# ATSAM4LC4A device description
Architecture: CORTEX-M4; Family: SAM4; Series: SAM4L
Registers are 32-bit, read-write, reset 0x0 unless marked. A register's access mark holds for its fields unless they carry their own. Offsets are from the block's base; [hi:lo] are bit positions; {n}, {i} and the like mark numbered series.

## AESA — Advanced Encryption Standard
Instances: AESA 0x400B0000
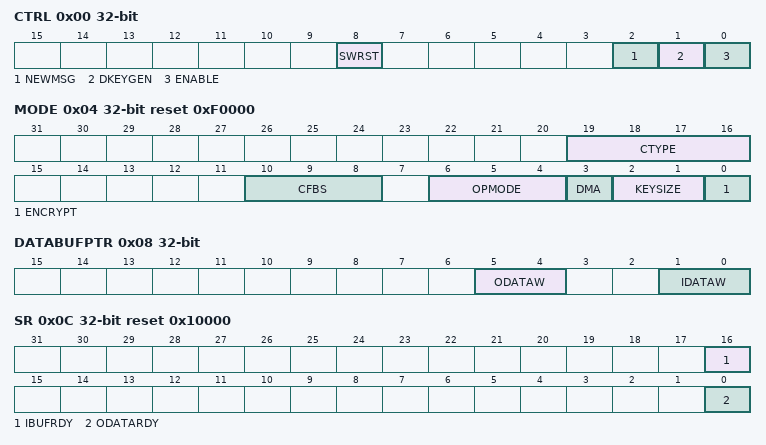
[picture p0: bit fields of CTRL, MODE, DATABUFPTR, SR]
0x00 CTRL — Control Register
  [8] SWRST — Software Reset
  [2] NEWMSG — New Message
  [1] DKEYGEN — Decryption Key Generate
  [0] ENABLE — Enable Module
0x04 MODE reset 0xF0000
  [19:16] CTYPE — Countermeasure Type
  [10:8] CFBS — Cipher Feedback Data Segment Size
  [6:4] OPMODE — Confidentiality Mode of Operation
  [3] DMA — DMA Mode
  [2:1] KEYSIZE
  [0] ENCRYPT — Encryption
0x08 DATABUFPTR — Data Buffer Pointer Register
  [5:4] ODATAW — Output Data Word
  [1:0] IDATAW — Input Data Word
0x0C SR ro reset 0x10000 — Status Register
  [16] IBUFRDY — Input Buffer Ready
  [0] ODATARDY — Output Data Ready
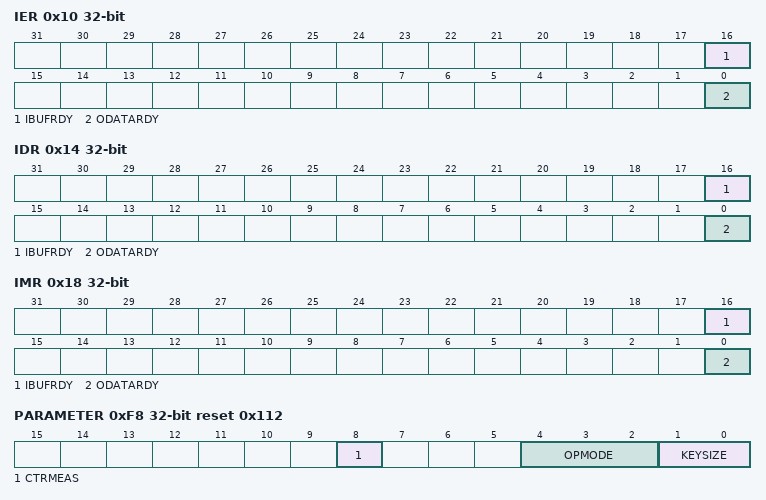
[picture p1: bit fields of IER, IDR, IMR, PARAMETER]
0x10 IER wo (atomic set of IMR) — Interrupt Enable Register
  [16] IBUFRDY — Input Buffer Ready Interrupt Enable
  [0] ODATARDY — Output Data Ready Interrupt Enable
0x14 IDR wo (atomic clear of IMR) — Interrupt Disable Register
  [16] IBUFRDY — Input Buffer Ready Interrupt Disable
  [0] ODATARDY — Output Data Ready Interrupt Disable
0x18 IMR ro — Interrupt Mask Register
  [16] IBUFRDY — Input Buffer Ready Interrupt Mask
  [0] ODATARDY — Output Data Ready Interrupt Mask
{0x20+4i} KEY[{i}] (i=0..7) wo
  [31:0] KEY0 — Key Word 0
{0x40+4i} INITVECT[{i}] (i=0..3) wo — Initialization Vector Register
  [31:0] INITVECT0 — Initialization Vector Word 0
0x50 IDATA wo — Input Data Register
  [31:0] IDATA — Input Data
0x60 ODATA ro — Output Data Register
  [31:0] ODATA — Output Data
0x70 DRNGSEED wo
  [31:0] SEED — DRNG Seed
0xF8 PARAMETER ro reset 0x112
  [8] CTRMEAS — Countermeasures
  [4:2] OPMODE — Maximum Number of Confidentiality Modes of Operation
  [1:0] KEYSIZE — Maximum Key Size
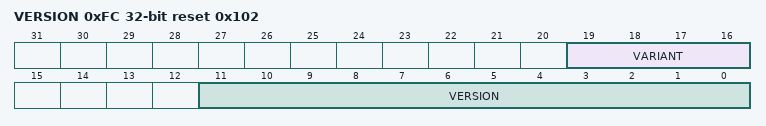
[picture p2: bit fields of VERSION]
0xFC VERSION ro reset 0x102
  [19:16] VARIANT — Variant Number
  [11:0] VERSION — Version Number

## BPM — Backup Power Manager
Instances: BPM 0x400F0000
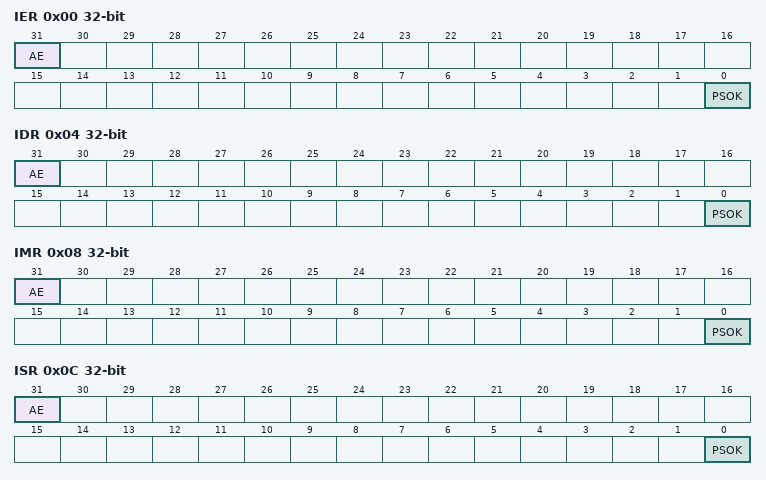
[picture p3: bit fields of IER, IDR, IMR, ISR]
0x00 IER wo (atomic set of IMR) — Interrupt Enable Register
  [31] AE — Access Error Interrupt Enable
  [0] PSOK — Power Scaling OK Interrupt Enable
0x04 IDR wo (atomic clear of IMR) — Interrupt Disable Register
  [31] AE — Access Error Interrupt Disable
  [0] PSOK — Power Scaling OK Interrupt Disable
0x08 IMR ro — Interrupt Mask Register
  [31] AE — Access Error Interrupt Mask
  [0] PSOK — Power Scaling OK Interrupt Mask
0x0C ISR ro — Interrupt Status Register
  [31] AE — Access Error Interrupt Status
  [0] PSOK — Power Scaling OK Interrupt Status
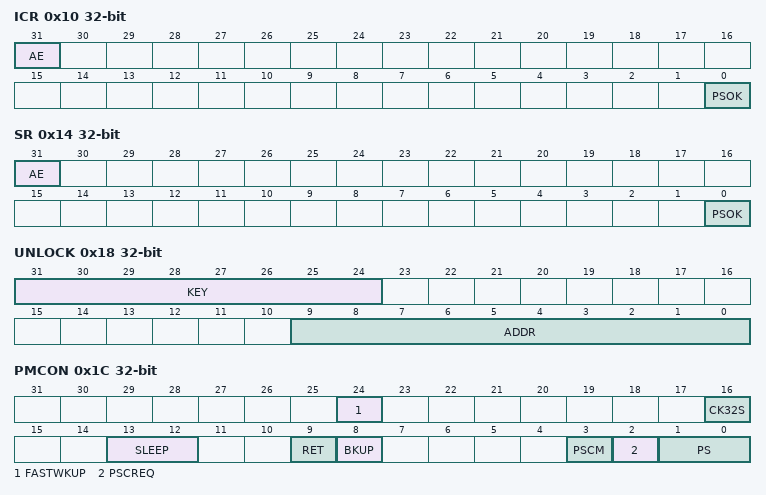
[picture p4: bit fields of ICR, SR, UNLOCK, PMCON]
0x10 ICR wo (atomic clear of ISR) — Interrupt Clear Register
  [31] AE — Access Error Interrupt Status Clear
  [0] PSOK — Power Scaling OK Interrupt Status Clear
0x14 SR ro — Status Register
  [31] AE — Access Error
  [0] PSOK — Power Scaling OK Status
0x18 UNLOCK wo
  [31:24] KEY — Unlock Key
  [9:0] ADDR — Unlock Address
0x1C PMCON — Power Mode Control Register
  [24] FASTWKUP — Fast Wakeup
  [16] CK32S — 32Khz-1Khz Clock Source Selection
  [13:12] SLEEP — SLEEP mode Configuration
  [9] RET — RETENTION Mode
  [8] BKUP — BACKUP Mode
  [3] PSCM — Power Scaling Change Mode
  [2] PSCREQ — Power Scaling Change Request
  [1:0] PS — Power Scaling Configuration Value
0x28 BKUPWCAUSE ro — Backup Wake up Cause Register
0x2C BKUPWEN — Backup Wake up Enable Register
0x30 BKUPPMUX — Backup Pin Muxing Register
  [8:0] BKUPPMUX — Backup Pin Muxing
0x34 IORET — Input Output Retention Register
  [0] RET — Retention on I/O lines after waking up from the BACKUP mode
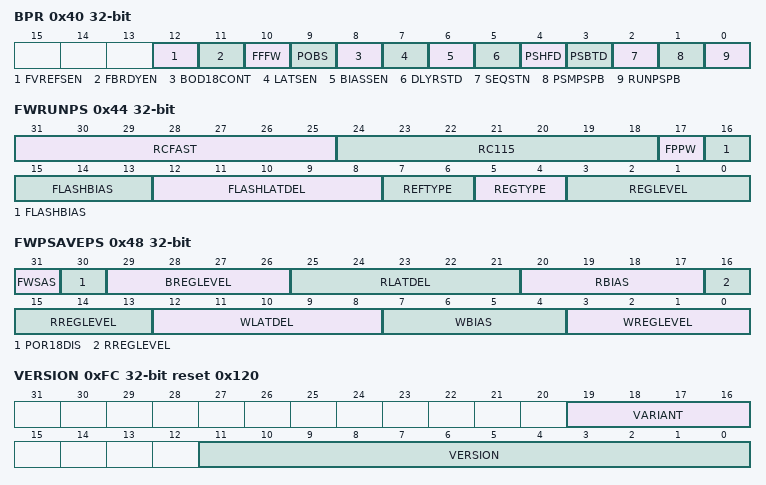
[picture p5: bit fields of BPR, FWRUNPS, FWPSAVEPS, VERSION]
0x40 BPR — Bypass Register
  [12] FVREFSEN — Flash Vref Switch Enable
  [11] FBRDYEN — Flash Bias Ready Enable
  [10] FFFW — Force Flash Fast Wakeup
  [9] POBS — Pico Uart Observability
  [8] BOD18CONT — BOD18 in continuous mode not disabled in WAIT/RET/BACKUP modes
  [7] LATSEN — Latdel Switch Enable
  [6] BIASSEN — Bias Switch Enable
  [5] DLYRSTD — Delaying Reset Disable
  [4] PSHFD — Power Scaling Halt Flash Until VREGOK Disable
  [3] PSBTD — Power Scaling Bias Timing Disable
  [2] SEQSTN — Sequencial Startup from ULP (Active Low)
  [1] PSMPSPB — Power Save Mode Power Scaling Preset Bypass
  [0] RUNPSPB — Run Mode Power Scaling Preset Bypass
0x44 FWRUNPS ro reset not defined — Factory Word Run PS Register
  [31:25] RCFAST — RCFAST Calibration Value
  [24:18] RC115 — RC 115KHZ Calibration Value
  [17] FPPW — Flash Pico Power Mode
  [16:13] FLASHBIAS — Flash Bias Value
  [12:8] FLASHLATDEL — Flash Latch Delay Value
  [7:6] REFTYPE — Reference Type
    0=BOTH; 1=BG; 2=LPBG; 3=INTERNAL
  [5:4] REGTYPE — Regulator Type
    0=NORMAL; 1=LP; 2=XULP
  [3:0] REGLEVEL — Regulator Voltage Level
0x48 FWPSAVEPS ro reset not defined — Factory Word Power Save PS Register
  [31] FWSAS — Flash Wait State Automatic Switching
  [30] POR18DIS — POR 18 Disable
  [29:26] BREGLEVEL — Backup mode Regulator Level
  [25:21] RLATDEL — Flash Latdel in Retention mode
  [20:17] RBIAS — Bias in Retention mode
  [16:13] RREGLEVEL — Retention mode Regulator Level
  [12:8] WLATDEL — Flash Latdel in wait mode
  [7:4] WBIAS — Bias in wait mode
  [3:0] WREGLEVEL — Wait mode Regulator Level
0xFC VERSION ro reset 0x120
  [19:16] VARIANT — Variant Number
  [11:0] VERSION — Version Number

## Notices in the file
Copyright (c) 2016 Atmel Corporation,
a wholly owned subsidiary of Microchip Technology Inc.
Licensed under the Apache License, Version 2.0 (the "License");
you may not use this file except in compliance with the License.
You may obtain a copy of the Licence at
http://www.apache.org/licenses/LICENSE-2.0
Unless required by applicable law or agreed to in writing, software
distributed under the License is distributed on an "AS IS" BASIS,
WITHOUT WARRANTIES OR CONDITIONS OF ANY KIND, either express or implied.
See the License for the specific language governing permissions and
limitations under the License.
